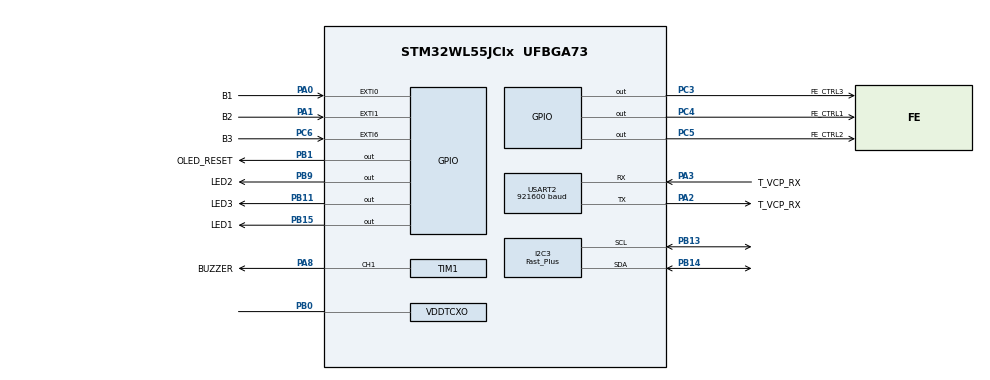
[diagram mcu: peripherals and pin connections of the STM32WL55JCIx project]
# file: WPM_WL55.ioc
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I2C3.I2C_Speed_Mode=I2C_Fast_Plus
I2C3.Timing=0x20000209
Mcu.Family=STM32WL
Mcu.Name=STM32WL55JCIx
Mcu.Package=UFBGA73
NVIC.EXTI0_IRQn=true\:0\:0\:false\:false\:true\:true\:true\:true
NVIC.EXTI1_IRQn=true\:0\:0\:false\:false\:true\:true\:true\:true
NVIC.EXTI9_5_IRQn=true\:0\:0\:false\:false\:true\:true\:true\:true
NVIC.PriorityGroup=NVIC_PRIORITYGROUP_4
NVIC.SUBGHZ_Radio_IRQn=true\:0\:0\:false\:false\:true\:true\:true\:true
NVIC.TIM16_IRQn=true\:0\:0\:false\:false\:true\:true\:true\:true
OSC_IN.Mode=HSE-TCXO
OSC_IN.Signal=RCC_OSC_IN
PA0.GPIO_Label=B1
PA0.GPIO_ModeDefaultEXTI=GPIO_MODE_IT_FALLING
PA0.GPIO_PuPd=GPIO_PULLUP
PA0.Signal=GPXTI0
PA1.GPIO_Label=B2
PA1.GPIO_ModeDefaultEXTI=GPIO_MODE_IT_FALLING
PA1.GPIO_PuPd=GPIO_PULLUP
PA1.Signal=GPXTI1
PA10.GPIO_Speed=GPIO_SPEED_FREQ_VERY_HIGH
PA10.Mode=RF-HSE32RDY
PA10.Signal=DEBUG_RF-HSE32RDY
PA11.GPIO_Speed=GPIO_SPEED_FREQ_VERY_HIGH
PA11.Mode=RF-NRESET
PA11.Signal=DEBUG_RF-NRESET
PA12.GPIO_Speed=GPIO_SPEED_FREQ_VERY_HIGH
PA12.Mode=RF-BUSY
PA12.Signal=DEBUG_RF-BUSY
PA13.Mode=Serial_Wire
PA13.Signal=DEBUG_JTMS-SWDIO
PA14.Mode=Serial_Wire
PA14.Signal=DEBUG_JTCK-SWCLK
PA2.GPIO_Label=T_VCP_RX
PA2.Mode=Asynchronous
PA2.Signal=USART2_TX
PA3.GPIO_Label=T_VCP_RX
PA3.Mode=Asynchronous
PA3.Signal=USART2_RX
PA4.GPIO_Speed=GPIO_SPEED_FREQ_VERY_HIGH
PA4.Mode=SUBGHZSPI-Monitoring
PA4.Signal=DEBUG_SUBGHZSPI-NSSOUT
PA5.GPIO_Speed=GPIO_SPEED_FREQ_VERY_HIGH
PA5.Mode=SUBGHZSPI-Monitoring
PA5.Signal=DEBUG_SUBGHZSPI-SCKOUT
PA6.GPIO_Speed=GPIO_SPEED_FREQ_VERY_HIGH
PA6.Mode=SUBGHZSPI-Monitoring
PA6.Signal=DEBUG_SUBGHZSPI-MISOOUT
PA7.GPIO_Speed=GPIO_SPEED_FREQ_VERY_HIGH
PA7.Mode=SUBGHZSPI-Monitoring
PA7.Signal=DEBUG_SUBGHZSPI-MOSIOUT
PA8.GPIO_Label=BUZZER
PA8.Signal=S_TIM1_CH1
PB0-VDD_TCXO.Mode=HSE-TCXO
PB0-VDD_TCXO.Signal=VDDTCXO
PB1.GPIO_Label=OLED_RESET
PB1.Signal=GPIO_Output
PB11.GPIO_Label=LED3
PB11.GPIO_Speed=GPIO_SPEED_FREQ_HIGH
PB11.Signal=GPIO_Output
PB13.Mode=I2C
PB13.Signal=I2C3_SCL
PB14.Mode=I2C
PB14.Signal=I2C3_SDA
PB15.GPIO_Label=LED1
PB15.GPIO_Speed=GPIO_SPEED_FREQ_HIGH
PB15.Signal=GPIO_Output
PB2.GPIO_Speed=GPIO_SPEED_FREQ_VERY_HIGH
PB2.Mode=RF-SMPSRDY
PB2.Signal=DEBUG_RF-SMPSRDY
PB3.GPIO_Label=IRQ0
PB3.GPIO_Speed=GPIO_SPEED_FREQ_VERY_HIGH
PB3.Signal=EVENTOUT
PB4.GPIO_Speed=GPIO_SPEED_FREQ_VERY_HIGH
PB4.Mode=RF-LDORDY
PB4.Signal=DEBUG_RF-LDORDY
PB5.GPIO_Label=IRQ1
PB5.GPIO_Speed=GPIO_SPEED_FREQ_VERY_HIGH
PB5.Signal=EVENTOUT
PB8.GPIO_Label=IRQ2
PB8.GPIO_Speed=GPIO_SPEED_FREQ_VERY_HIGH
PB8.Signal=EVENTOUT
PB9.GPIO_FM9=__NULL
PB9.GPIO_Label=LED2
PB9.GPIO_Speed=GPIO_SPEED_FREQ_HIGH
PB9.Signal=GPIO_Output
PC14-OSC32_IN.Mode=LSE-External-Oscillator
PC14-OSC32_IN.Signal=RCC_OSC32_IN
PC15-OSC32_OUT.Mode=LSE-External-Oscillator
PC15-OSC32_OUT.Signal=RCC_OSC32_OUT
PC3.GPIO_Label=FE_CTRL3
PC3.GPIO_Speed=GPIO_SPEED_FREQ_VERY_HIGH
PC3.Signal=GPIO_Output
PC4.GPIO_Label=FE_CTRL1
PC4.GPIO_Speed=GPIO_SPEED_FREQ_VERY_HIGH
PC4.Signal=GPIO_Output
PC5.GPIO_Label=FE_CTRL2
PC5.GPIO_Speed=GPIO_SPEED_FREQ_VERY_HIGH
PC5.Signal=GPIO_Output
PC6.GPIO_Label=B3
PC6.GPIO_ModeDefaultEXTI=GPIO_MODE_IT_FALLING
PC6.GPIO_PuPd=GPIO_PULLUP
PC6.Signal=GPXTI6
ProjectManager.HeapSize=0x200
ProjectManager.StackSize=0x400
ProjectManager.TargetToolchain=STM32CubeIDE
RCC.AHBFreq_Value=48000000
RCC.APB1Freq_Value=48000000
RCC.APB1TimFreq_Value=48000000
RCC.APB2Freq_Value=48000000
RCC.APB2TimFreq_Value=48000000
RCC.APB3Freq_Value=48000000
RCC.CortexFreq_Value=48000000
RCC.HCLKFreq_Value=48000000
RCC.HSE_VALUE=32000000
RCC.HSI_VALUE=16000000
RCC.LSE_VALUE=32768
RCC.MSIClockRange=RCC_MSIRANGE_11
RCC.SYSCLKFreq_VALUE=48000000
RCC.VCOOutputFreq_Value=384000000
SH.S_TIM1_CH1.0=TIM1_CH1,PWM Generation1 CH1
SUBGHZ.BaudratePrescaler=SUBGHZSPI_BAUDRATEPRESCALER_4
TIM1.Channel-PWM\ Generation1\ CH1=TIM_CHANNEL_1
TIM1.Period=(250 - 1)
TIM1.Prescaler=(48 - 1)
TIM16.Period=TIM16_ARR
TIM16.Prescaler=TIM16_PSC
USART2.BaudRate=921600
USART2.VirtualMode-Asynchronous=VM_ASYNC
VP_SUBGHZ_VS_SUBGHZ.Mode=SUBGHZ_Activate
VP_TIM16_VS_ClockSourceINT.Mode=Enable_Timer
VP_TIM1_VS_ClockSourceINT.Mode=Internal
board=NUCLEO-WL55JC1

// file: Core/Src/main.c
/* USER CODE BEGIN Header */
/* USER CODE END Header */
#include "main.h"
#include "i2c.h"
#include "subghz.h"
#include "tim.h"
#include "usart.h"
#include "gpio.h"

/* USER CODE BEGIN Includes */

#include "app.h"	// All main logic within "app.c"

/* USER CODE END Includes */

void SystemClock_Config(void);

int main(void)
{

  /* MCU Configuration--------------------------------------------------------*/

  /* Reset of all peripherals, Initializes the Flash interface and the Systick. */
  HAL_Init();

  /* Configure the system clock */
  SystemClock_Config();

  /* Initialize all configured peripherals */
  MX_GPIO_Init();
  MX_USART2_UART_Init();
  MX_SUBGHZ_Init();
  MX_I2C3_Init();
  MX_TIM1_Init();
  MX_TIM16_Init();
  /* USER CODE BEGIN 2 */

  APP_Init();		// Program enters here and never returns:
  	  	  			// All main logic within "app.c"

  /* USER CODE END 2 */

  /* Infinite loop */

}

void SystemClock_Config(void)
{
  RCC_OscInitTypeDef RCC_OscInitStruct = {0};
  RCC_ClkInitTypeDef RCC_ClkInitStruct = {0};

  /** Configure LSE Drive Capability
  */
  HAL_PWR_EnableBkUpAccess();
  __HAL_RCC_LSEDRIVE_CONFIG(RCC_LSEDRIVE_LOW);

  /** Configure the main internal regulator output voltage
  */
  __HAL_PWR_VOLTAGESCALING_CONFIG(PWR_REGULATOR_VOLTAGE_SCALE1);

  /** Initializes the CPU, AHB and APB buses clocks
  */
  RCC_OscInitStruct.OscillatorType = RCC_OSCILLATORTYPE_LSE|RCC_OSCILLATORTYPE_MSI;
  RCC_OscInitStruct.LSEState = RCC_LSE_ON;
  RCC_OscInitStruct.MSIState = RCC_MSI_ON;
  RCC_OscInitStruct.MSICalibrationValue = RCC_MSICALIBRATION_DEFAULT;
  RCC_OscInitStruct.MSIClockRange = RCC_MSIRANGE_11;
  RCC_OscInitStruct.PLL.PLLState = RCC_PLL_NONE;
  if (HAL_RCC_OscConfig(&RCC_OscInitStruct) != HAL_OK)
  {
    Error_Handler();
  }

  /** Configure the SYSCLKSource, HCLK, PCLK1 and PCLK2 clocks dividers
  */
  RCC_ClkInitStruct.ClockType = RCC_CLOCKTYPE_HCLK3|RCC_CLOCKTYPE_HCLK
                              |RCC_CLOCKTYPE_SYSCLK|RCC_CLOCKTYPE_PCLK1
                              |RCC_CLOCKTYPE_PCLK2;
  RCC_ClkInitStruct.SYSCLKSource = RCC_SYSCLKSOURCE_MSI;
  RCC_ClkInitStruct.AHBCLKDivider = RCC_SYSCLK_DIV1;
  RCC_ClkInitStruct.APB1CLKDivider = RCC_HCLK_DIV1;
  RCC_ClkInitStruct.APB2CLKDivider = RCC_HCLK_DIV1;
  RCC_ClkInitStruct.AHBCLK3Divider = RCC_SYSCLK_DIV1;

  if (HAL_RCC_ClockConfig(&RCC_ClkInitStruct, FLASH_LATENCY_2) != HAL_OK)
  {
    Error_Handler();
  }
}

void Error_Handler(void)
{
}
